# emac register map
Vendor: Texas Instruments
Peripheral module from a debugger description file (folder tm4c129xkczad).
Registers are 32-bit, read-write, no defined reset value unless marked. A register's access mark holds for its fields unless they carry their own. Offsets are as the file gives them; lines under a group give offsets from that group; [hi:lo] are bit positions; {n}, {i} and the like mark numbered series; 'fields as' and 'values as' point back to an identical list; <NAME> marks a mode.

## EMAC0 — EMAC register offsets
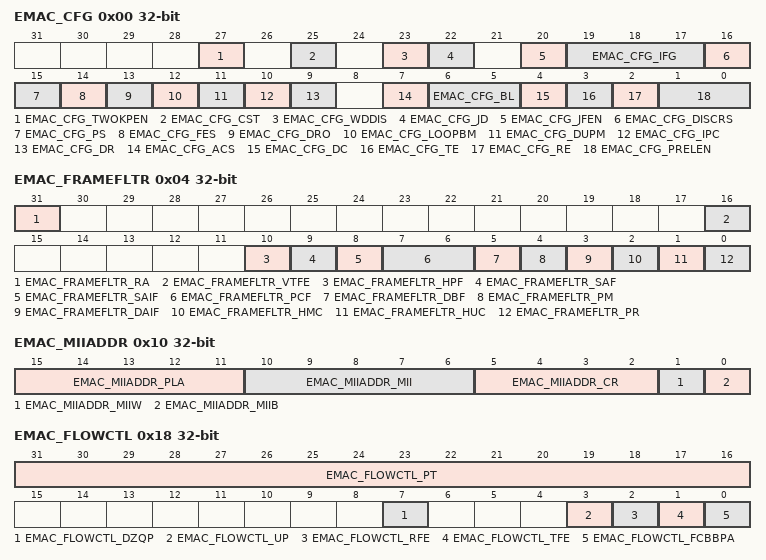
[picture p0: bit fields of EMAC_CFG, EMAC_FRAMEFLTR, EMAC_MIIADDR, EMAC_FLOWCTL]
0x00 EMAC_CFG — Ethernet MAC Configuration
  [27] EMAC_CFG_TWOKPEN — IEEE 802
  [25] EMAC_CFG_CST — CRC Stripping for Type Frames
  [23] EMAC_CFG_WDDIS — Watchdog Disable
  [22] EMAC_CFG_JD — Jabber Disable
  [20] EMAC_CFG_JFEN — Jumbo Frame Enable
  [19:17] EMAC_CFG_IFG — Inter-Frame Gap (IFG)
    0=96 bit times; 1=88 bit times; 2=80 bit times; 3=72 bit times; 4=64 bit times; 5=56 bit times; 6=48 bit times; 7=40 bit times
  [16] EMAC_CFG_DISCRS — Disable Carrier Sense During Transmission
  [15] EMAC_CFG_PS — Port Select
  [14] EMAC_CFG_FES — Speed
  [13] EMAC_CFG_DRO — Disable Receive Own
  [12] EMAC_CFG_LOOPBM — Loopback Mode
  [11] EMAC_CFG_DUPM — Duplex Mode
  [10] EMAC_CFG_IPC — Checksum Offload
  [9] EMAC_CFG_DR — Disable Retry
  [7] EMAC_CFG_ACS — Automatic Pad or CRC Stripping
  [6:5] EMAC_CFG_BL — Back-Off Limit
    0=k = min (n,10); 1=k = min (n,8); 2=k = min (n,4); 3=k = min (n,1)
  [4] EMAC_CFG_DC — Deferral Check
  [3] EMAC_CFG_TE — Transmitter Enable
  [2] EMAC_CFG_RE — Receiver Enable
  [1:0] EMAC_CFG_PRELEN — Preamble Length for Transmit Frames
    0=7 bytes of preamble; 1=5 bytes of preamble; 2=3 bytes of preamble
0x04 EMAC_FRAMEFLTR — Ethernet MAC Frame Filter
  [31] EMAC_FRAMEFLTR_RA — Receive All
  [16] EMAC_FRAMEFLTR_VTFE — VLAN Tag Filter Enable
  [10] EMAC_FRAMEFLTR_HPF — Hash or Perfect Filter
  [9] EMAC_FRAMEFLTR_SAF — Source Address Filter Enable
  [8] EMAC_FRAMEFLTR_SAIF — Source Address (SA) Inverse Filtering
  [7:6] EMAC_FRAMEFLTR_PCF — Pass Control Frames
    0=EMAC_FRAMEFLTR_PCF_ALL (The MAC filters all control frames from reaching application); 1=EMAC_FRAMEFLTR_PCF_PAUSE (MAC forwards all control frames except PAUSE control frames to application even if they fail the address filter); 2=EMAC_FRAMEFLTR_PCF_NONE (MAC forwards all control frames to application even if they fail the address Filter); 3=EMAC_FRAMEFLTR_PCF_ADDR (MAC forwards control frames that pass the address Filter)
  [5] EMAC_FRAMEFLTR_DBF — Disable Broadcast Frames
  [4] EMAC_FRAMEFLTR_PM — Pass All Multicast
  [3] EMAC_FRAMEFLTR_DAIF — Destination Address (DA) Inverse Filtering
  [2] EMAC_FRAMEFLTR_HMC — Hash Multicast
  [1] EMAC_FRAMEFLTR_HUC — Hash Unicast
  [0] EMAC_FRAMEFLTR_PR — Promiscuous Mode
0x08 EMAC_HASHTBLH — Ethernet MAC Hash Table High
  [31:0] EMAC_HASHTBLH_HTH — Hash Table High
0x0C EMAC_HASHTBLL — Ethernet MAC Hash Table Low
  [31:0] EMAC_HASHTBLL_HTL — Hash Table Low
0x10 EMAC_MIIADDR — Ethernet MAC MII Address
  [15:11] EMAC_MIIADDR_PLA — Physical Layer Address
  [10:6] EMAC_MIIADDR_MII — MII Register
  [5:2] EMAC_MIIADDR_CR — Clock Reference Frequency Selection
    0=EMAC_MIIADDR_CR_60_100 (The frequency of the System Clock is 60 to 100 MHz providing a MDIO clock of SYSCLK/42); 4=EMAC_MIIADDR_CR_100_150 (The frequency of the System Clock is 100 to 150 MHz providing a MDIO clock of SYSCLK/62); 8=EMAC_MIIADDR_CR_20_35 (The frequency of the System Clock is 20-35 MHz providing a MDIO clock of System Clock/16); 12=EMAC_MIIADDR_CR_35_60 (The frequency of the System Clock is 35 to 60 MHz providing a MDIO clock of System Clock/26)
  [1] EMAC_MIIADDR_MIIW — MII Write
  [0] EMAC_MIIADDR_MIIB — MII Busy
0x14 EMAC_MIIDATA — Ethernet MAC MII Data Register
  [15:0] EMAC_MIIDATA_DATA — MII Data
0x18 EMAC_FLOWCTL — Ethernet MAC Flow Control
  [31:16] EMAC_FLOWCTL_PT — Pause Time
  [7] EMAC_FLOWCTL_DZQP — Disable Zero-Quanta Pause
  [3] EMAC_FLOWCTL_UP — Unicast Pause Frame Detect
  [2] EMAC_FLOWCTL_RFE — Receive Flow Control Enable
  [1] EMAC_FLOWCTL_TFE — Transmit Flow Control Enable
  [0] EMAC_FLOWCTL_FCBBPA — Flow Control Busy or Back-pressure Activate
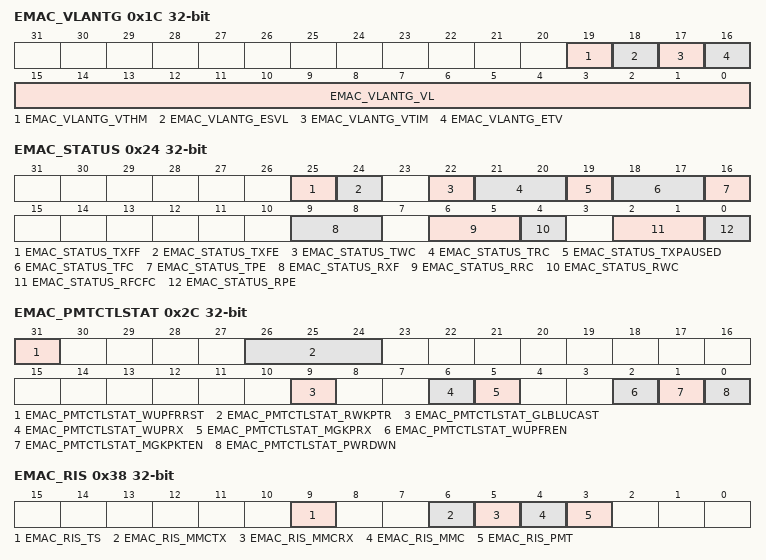
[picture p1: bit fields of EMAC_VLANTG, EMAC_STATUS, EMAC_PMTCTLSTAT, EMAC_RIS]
0x1C EMAC_VLANTG — Ethernet MAC VLAN Tag
  [19] EMAC_VLANTG_VTHM — VLAN Tag Hash Table Match Enable
  [18] EMAC_VLANTG_ESVL — Enable S-VLAN
  [17] EMAC_VLANTG_VTIM — VLAN Tag Inverse Match Enable
  [16] EMAC_VLANTG_ETV — Enable 12-Bit VLAN Tag Comparison
  [15:0] EMAC_VLANTG_VL — VLAN Tag Identifier for Receive Frames
0x24 EMAC_STATUS ro — Ethernet MAC Status
  [25] EMAC_STATUS_TXFF — TX/RX Controller TX FIFO Full Status
  [24] EMAC_STATUS_TXFE — TX/RX Controller TX FIFO Not Empty Status
  [22] EMAC_STATUS_TWC — TX/RX Controller TX FIFO Write Controller Active Status
  [21:20] EMAC_STATUS_TRC — TX/RX Controller's TX FIFO Read Controller Status
    0=EMAC_STATUS_TRC_IDLE (IDLE state); 1=EMAC_STATUS_TRC_READ (READ state (transferring data to MAC transmitter)); 2=EMAC_STATUS_TRC_WAIT (Waiting for TX Status from MAC transmitter); 3=EMAC_STATUS_TRC_WRFLUSH (Writing the received TX Status or flushing the TX FIFO)
  [19] EMAC_STATUS_TXPAUSED — MAC Transmitter PAUSE
  [18:17] EMAC_STATUS_TFC — MAC Transmit Frame Controller Status
    0=EMAC_STATUS_TFC_IDLE (IDLE state); 1=EMAC_STATUS_TFC_STATUS (Waiting for status of previous frame or IFG or backoff period to be over); 2=EMAC_STATUS_TFC_PAUSE (Generating and transmitting a PAUSE control frame (in the full-duplex mode)); 3=EMAC_STATUS_TFC_INPUT (Transferring input frame for transmission)
  [16] EMAC_STATUS_TPE — MAC MII Transmit Protocol Engine Status
  [9:8] EMAC_STATUS_RXF — TX/RX Controller RX FIFO Fill-level Status
    0=EMAC_STATUS_RXF_EMPTY (RX FIFO Empty); 1=EMAC_STATUS_RXF_BELOW (RX FIFO fill level is below the flow-control deactivate threshold); 2=EMAC_STATUS_RXF_ABOVE (RX FIFO fill level is above the flow-control activate threshold); 3=EMAC_STATUS_RXF_FULL (RX FIFO Full)
  [6:5] EMAC_STATUS_RRC — TX/RX Controller Read Controller State
    0=EMAC_STATUS_RRC_IDLE (IDLE state); 1=EMAC_STATUS_RRC_STATUS (Reading frame data); 2=EMAC_STATUS_RRC_DATA (Reading frame status (or timestamp)); 3=EMAC_STATUS_RRC_FLUSH (Flushing the frame data and status)
  [4] EMAC_STATUS_RWC — TX/RX Controller RX FIFO Write Controller Active Status
  [2:1] EMAC_STATUS_RFCFC — MAC Receive Frame Controller FIFO Status
  [0] EMAC_STATUS_RPE — MAC MII Receive Protocol Engine Status
0x28 EMAC_RWUFF — Ethernet MAC Remote Wake-Up Frame Filter
  [31:0] EMAC_RWUFF_WAKEUPFIL — Remote Wake-Up Frame Filter
0x2C EMAC_PMTCTLSTAT — Ethernet MAC PMT Control and Status Register
  [31] EMAC_PMTCTLSTAT_WUPFRRST — Wake-Up Frame Filter Register Pointer Reset
  [26:24] EMAC_PMTCTLSTAT_RWKPTR — Remote Wake-Up FIFO Pointer
  [9] EMAC_PMTCTLSTAT_GLBLUCAST — Global Unicast
  [6] EMAC_PMTCTLSTAT_WUPRX — Wake-Up Frame Received
  [5] EMAC_PMTCTLSTAT_MGKPRX — Magic Packet Received
  [2] EMAC_PMTCTLSTAT_WUPFREN — Wake-Up Frame Enable
  [1] EMAC_PMTCTLSTAT_MGKPKTEN — Magic Packet Enable
  [0] EMAC_PMTCTLSTAT_PWRDWN — Power Down
0x38 EMAC_RIS ro — Ethernet MAC Raw Interrupt Status
  [9] EMAC_RIS_TS — Timestamp Interrupt Status
  [6] EMAC_RIS_MMCTX — MMC Transmit Interrupt Status
  [5] EMAC_RIS_MMCRX — MMC Receive Interrupt Status
  [4] EMAC_RIS_MMC — MMC Interrupt Status
  [3] EMAC_RIS_PMT — PMT Interrupt Status
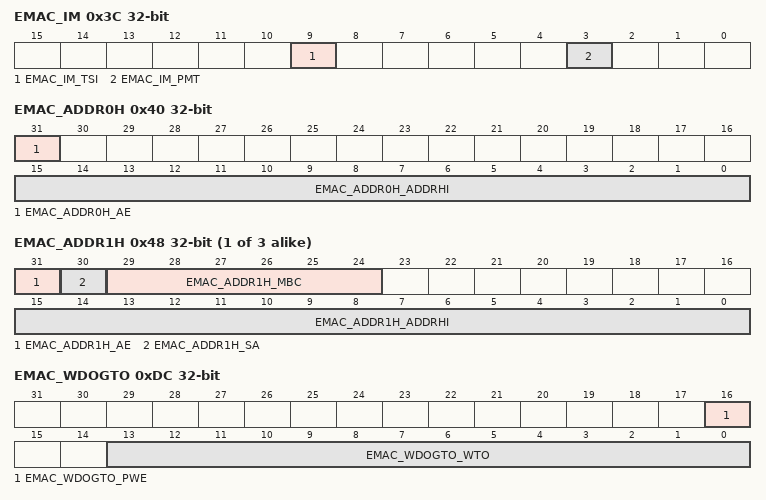
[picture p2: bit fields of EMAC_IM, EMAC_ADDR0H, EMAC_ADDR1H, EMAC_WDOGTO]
0x3C EMAC_IM — Ethernet MAC Interrupt Mask
  [9] EMAC_IM_TSI — Timestamp Interrupt Mask
  [3] EMAC_IM_PMT — PMT Interrupt Mask
0x40 EMAC_ADDR0H — Ethernet MAC Address 0 High
  [31] EMAC_ADDR0H_AE — Address Enable
  [15:0] EMAC_ADDR0H_ADDRHI — MAC Address0 [47:32]
0x44 EMAC_ADDR0L — Ethernet MAC Address 0 Low Register
  [31:0] EMAC_ADDR0L_ADDRLO — MAC Address0 [31:0]
{0x40+8i} EMAC_ADDR{i}H (i=1..3) — Ethernet MAC Address {i} High
  [31] EMAC_ADDR{i}H_AE — Address Enable
  [30] EMAC_ADDR{i}H_SA — Source Address
  [29:24] EMAC_ADDR{i}H_MBC — Mask Byte Control
  [15:0] EMAC_ADDR{i}H_ADDRHI — MAC Address{i} [47:32]
{0x44+8i} EMAC_ADDR{i}L (i=1..3) — Ethernet MAC Address {i} Low
  [31:0] EMAC_ADDR{i}L_ADDRLO — MAC Address{i} [31:0]
0xDC EMAC_WDOGTO — Ethernet MAC Watchdog Timeout
  [16] EMAC_WDOGTO_PWE — Programmable Watchdog Enable
  [13:0] EMAC_WDOGTO_WTO — Watchdog Timeout
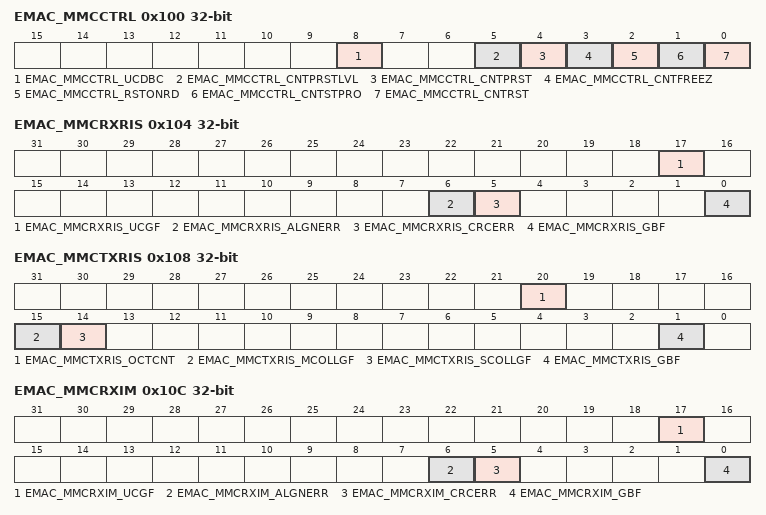
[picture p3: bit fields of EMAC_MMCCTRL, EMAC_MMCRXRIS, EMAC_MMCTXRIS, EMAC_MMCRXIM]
0x100 EMAC_MMCCTRL — Ethernet MAC MMC Control
  [8] EMAC_MMCCTRL_UCDBC — Update MMC Counters for Dropped Broadcast Frames
  [5] EMAC_MMCCTRL_CNTPRSTLVL — Full/Half Preset Level Value
  [4] EMAC_MMCCTRL_CNTPRST — Counters Preset
  [3] EMAC_MMCCTRL_CNTFREEZ — MMC Counter Freeze
  [2] EMAC_MMCCTRL_RSTONRD — Reset on Read
  [1] EMAC_MMCCTRL_CNTSTPRO — Counters Stop Rollover
  [0] EMAC_MMCCTRL_CNTRST — Counters Reset
0x104 EMAC_MMCRXRIS ro — Ethernet MAC MMC Receive Raw Interrupt Status
  [17] EMAC_MMCRXRIS_UCGF — MMC Receive Unicast Good Frame Counter Interrupt Status
  [6] EMAC_MMCRXRIS_ALGNERR — MMC Receive Alignment Error Frame Counter Interrupt Status
  [5] EMAC_MMCRXRIS_CRCERR — MMC Receive CRC Error Frame Counter Interrupt Status
  [0] EMAC_MMCRXRIS_GBF — MMC Receive Good Bad Frame Counter Interrupt Status
0x108 EMAC_MMCTXRIS ro — Ethernet MAC MMC Transmit Raw Interrupt Status
  [20] EMAC_MMCTXRIS_OCTCNT — Octet Counter Interrupt Status
  [15] EMAC_MMCTXRIS_MCOLLGF — MMC Transmit Multiple Collision Good Frame Counter Interrupt Status
  [14] EMAC_MMCTXRIS_SCOLLGF — MMC Transmit Single Collision Good Frame Counter Interrupt Status
  [1] EMAC_MMCTXRIS_GBF — MMC Transmit Good Bad Frame Counter Interrupt Status
0x10C EMAC_MMCRXIM — Ethernet MAC MMC Receive Interrupt Mask
  [17] EMAC_MMCRXIM_UCGF — MMC Receive Unicast Good Frame Counter Interrupt Mask
  [6] EMAC_MMCRXIM_ALGNERR — MMC Receive Alignment Error Frame Counter Interrupt Mask
  [5] EMAC_MMCRXIM_CRCERR — MMC Receive CRC Error Frame Counter Interrupt Mask
  [0] EMAC_MMCRXIM_GBF — MMC Receive Good Bad Frame Counter Interrupt Mask
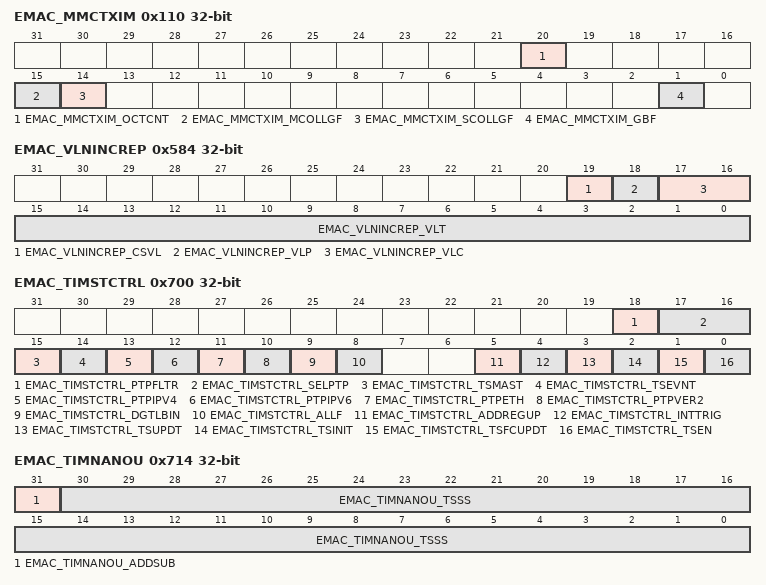
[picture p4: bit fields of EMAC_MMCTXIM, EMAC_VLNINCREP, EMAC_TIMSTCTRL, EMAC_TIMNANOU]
0x110 EMAC_MMCTXIM — Ethernet MAC MMC Transmit Interrupt Mask
  [20] EMAC_MMCTXIM_OCTCNT — MMC Transmit Good Octet Counter Interrupt Mask
  [15] EMAC_MMCTXIM_MCOLLGF — MMC Transmit Multiple Collision Good Frame Counter Interrupt Mask
  [14] EMAC_MMCTXIM_SCOLLGF — MMC Transmit Single Collision Good Frame Counter Interrupt Mask
  [1] EMAC_MMCTXIM_GBF — MMC Transmit Good Bad Frame Counter Interrupt Mask
0x118 EMAC_TXCNTGB ro — Ethernet MAC Transmit Frame Count for Good and Bad Frames
  [31:0] EMAC_TXCNTGB_TXFRMGB — This field indicates the number of good and bad frames transmitted, exclusive of retried frames
0x14C EMAC_TXCNTSCOL ro — Ethernet MAC Transmit Frame Count for Frames Transmitted after Single Collision
  [31:0] EMAC_TXCNTSCOL_TXSNGLCOLG — This field indicates the number of successfully transmitted frames after a single collision in the half-duplex mode
0x150 EMAC_TXCNTMCOL ro — Ethernet MAC Transmit Frame Count for Frames Transmitted after Multiple Collisions
  [31:0] EMAC_TXCNTMCOL_TXMULTCOLG — This field indicates the number of successfully transmitted frames after multiple collisions in the half-duplex mode
0x164 EMAC_TXOCTCNTG ro — Ethernet MAC Transmit Octet Count Good
  [31:0] EMAC_TXOCTCNTG_TXOCTG — This field indicates the number of bytes transmitted, exclusive of preamble, in good frames
0x180 EMAC_RXCNTGB ro — Ethernet MAC Receive Frame Count for Good and Bad Frames
  [31:0] EMAC_RXCNTGB_RXFRMGB — This field indicates the number of received good and bad frames
0x194 EMAC_RXCNTCRCERR ro — Ethernet MAC Receive Frame Count for CRC Error Frames
  [31:0] EMAC_RXCNTCRCERR_RXCRCERR — This field indicates the number of frames received with CRC error
0x198 EMAC_RXCNTALGNERR ro — Ethernet MAC Receive Frame Count for Alignment Error Frames
  [31:0] EMAC_RXCNTALGNERR_RXALGNERR — This field indicates the number of frames received with alignment (dribble) error
0x1C4 EMAC_RXCNTGUNI ro — Ethernet MAC Receive Frame Count for Good Unicast Frames
  [31:0] EMAC_RXCNTGUNI_RXUCASTG — This field indicates the number of received good unicast frames
0x584 EMAC_VLNINCREP — Ethernet MAC VLAN Tag Inclusion or Replacement
  [19] EMAC_VLNINCREP_CSVL — C-VLAN or S-VLAN
  [18] EMAC_VLNINCREP_VLP — VLAN Priority Control
  [17:16] EMAC_VLNINCREP_VLC — VLAN Tag Control in Transmit Frames
    0=EMAC_VLNINCREP_VLC_NONE (No VLAN tag deletion, insertion, or replacement); 1=EMAC_VLNINCREP_VLC_TAGDEL (VLAN tag deletion); 2=EMAC_VLNINCREP_VLC_TAGINS (VLAN tag insertion); 3=EMAC_VLNINCREP_VLC_TAGREP (VLAN tag replacement)
  [15:0] EMAC_VLNINCREP_VLT — VLAN Tag for Transmit Frames
0x588 EMAC_VLANHASH — Ethernet MAC VLAN Hash Table
  [15:0] EMAC_VLANHASH_VLHT — VLAN Hash Table
0x700 EMAC_TIMSTCTRL — Ethernet MAC Timestamp Control
  [18] EMAC_TIMSTCTRL_PTPFLTR — Enable MAC address for PTP Frame Filtering
  [17:16] EMAC_TIMSTCTRL_SELPTP — Select PTP packets for Taking Snapshots
  [15] EMAC_TIMSTCTRL_TSMAST — Enable Snapshot for Messages Relevant to Master
  [14] EMAC_TIMSTCTRL_TSEVNT — Enable Timestamp Snapshot for Event Messages
  [13] EMAC_TIMSTCTRL_PTPIPV4 — Enable Processing of PTP Frames Sent over IPv4-UDP
  [12] EMAC_TIMSTCTRL_PTPIPV6 — Enable Processing of PTP Frames Sent Over IPv6-UDP
  [11] EMAC_TIMSTCTRL_PTPETH — Enable Processing of PTP Over Ethernet Frames
  [10] EMAC_TIMSTCTRL_PTPVER2 — Enable PTP Packet Processing For Version 2 Format
  [9] EMAC_TIMSTCTRL_DGTLBIN — Timestamp Digital or Binary Rollover Control
  [8] EMAC_TIMSTCTRL_ALLF — Enable Timestamp For All Frames
  [5] EMAC_TIMSTCTRL_ADDREGUP — Addend Register Update
  [4] EMAC_TIMSTCTRL_INTTRIG — Timestamp Interrupt Trigger Enable
  [3] EMAC_TIMSTCTRL_TSUPDT — Timestamp Update
  [2] EMAC_TIMSTCTRL_TSINIT — Timestamp Initialize
  [1] EMAC_TIMSTCTRL_TSFCUPDT — Timestamp Fine or Coarse Update
  [0] EMAC_TIMSTCTRL_TSEN — Timestamp Enable
0x704 EMAC_SUBSECINC — Ethernet MAC Sub-Second Increment
  [7:0] EMAC_SUBSECINC_SSINC — Sub-second Increment Value
0x708 EMAC_TIMSEC ro — Ethernet MAC System Time - Seconds
  [31:0] EMAC_TIMSEC_TSS — Timestamp Second
0x70C EMAC_TIMNANO ro — Ethernet MAC System Time - Nanoseconds
  [30:0] EMAC_TIMNANO_TSSS — Timestamp Sub-Seconds
0x710 EMAC_TIMSECU — Ethernet MAC System Time - Seconds Update
  [31:0] EMAC_TIMSECU_TSS — Timestamp Second
0x714 EMAC_TIMNANOU — Ethernet MAC System Time - Nanoseconds Update
  [31] EMAC_TIMNANOU_ADDSUB — Add or subtract time
  [30:0] EMAC_TIMNANOU_TSSS — Timestamp Sub-Second
0x718 EMAC_TIMADD — Ethernet MAC Timestamp Addend
  [31:0] EMAC_TIMADD_TSAR — Timestamp Addend Register
0x71C EMAC_TARGSEC — Ethernet MAC Target Time Seconds
  [31:0] EMAC_TARGSEC_TSTR — Target Time Seconds Register
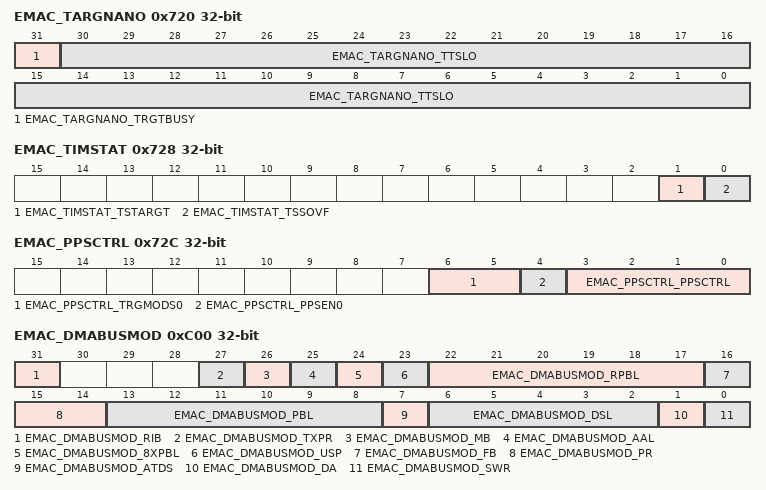
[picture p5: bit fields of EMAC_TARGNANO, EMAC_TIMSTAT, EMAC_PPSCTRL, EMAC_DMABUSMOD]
0x720 EMAC_TARGNANO — Ethernet MAC Target Time Nanoseconds
  [31] EMAC_TARGNANO_TRGTBUSY — Target Time Register Busy
  [30:0] EMAC_TARGNANO_TTSLO — Target Timestamp Low Register
0x724 EMAC_HWORDSEC — Ethernet MAC System Time-Higher Word Seconds
  [15:0] EMAC_HWORDSEC_TSHWR — Target Timestamp Higher Word Register
0x728 EMAC_TIMSTAT ro — Ethernet MAC Timestamp Status
  [1] EMAC_TIMSTAT_TSTARGT — Timestamp Target Time Reached
  [0] EMAC_TIMSTAT_TSSOVF — Timestamp Seconds Overflow
0x72C EMAC_PPSCTRL — Ethernet MAC PPS Control
  [6:5] EMAC_PPSCTRL_TRGMODS0 — Target Time Register Mode for PPS0 Output
    0=EMAC_PPSCTRL_TRGMODS0_INTONLY (Indicates that the Target Time registers are programmed only for generating the interrupt event); 2=EMAC_PPSCTRL_TRGMODS0_INTPPS0 (Indicates that the Target Time registers are programmed for generating the interrupt event and starting or stopping the generation of the EN0PPS output signal); 3=EMAC_PPSCTRL_TRGMODS0_PPS0ONLY (Indicates that the Target Time registers are programmed only for starting or stopping the generation of the EN0PPS output signal. No interrupt is asserted)
  [4] EMAC_PPSCTRL_PPSEN0 — Flexible PPS Output Mode Enable
  [3:0] EMAC_PPSCTRL_PPSCTRL — EN0PPS Output Frequency Control (PPSCTRL) or Command Control (PPSCMD)
0x760 EMAC_PPS0INTVL — Ethernet MAC PPS0 Interval
  [31:0] EMAC_PPS0INTVL_PPS0INT — PPS0 Output Signal Interval
0x764 EMAC_PPS0WIDTH — Ethernet MAC PPS0 Width
  [31:0] EMAC_PPS0WIDTH — EN0PPS Output Signal Width
0xC00 EMAC_DMABUSMOD — Ethernet MAC DMA Bus Mode
  [31] EMAC_DMABUSMOD_RIB — Rebuild Burst
  [27] EMAC_DMABUSMOD_TXPR — Transmit Priority
  [26] EMAC_DMABUSMOD_MB — Mixed Burst
  [25] EMAC_DMABUSMOD_AAL — Address Aligned Beats
  [24] EMAC_DMABUSMOD_8XPBL — 8 x Programmable Burst Length (PBL) Mode
  [23] EMAC_DMABUSMOD_USP — Use Separate Programmable Burst Length (PBL)
  [22:17] EMAC_DMABUSMOD_RPBL — RX DMA Programmable Burst Length (PBL)
  [16] EMAC_DMABUSMOD_FB — Fixed Burst
  [15:14] EMAC_DMABUSMOD_PR — Priority Ratio
  [13:8] EMAC_DMABUSMOD_PBL — Programmable Burst Length
  [7] EMAC_DMABUSMOD_ATDS — Alternate Descriptor Size
  [6:2] EMAC_DMABUSMOD_DSL — Descriptor Skip Length
  [1] EMAC_DMABUSMOD_DA — DMA Arbitration Scheme
  [0] EMAC_DMABUSMOD_SWR — DMA Software Reset
0xC04 EMAC_TXPOLLD wo — Ethernet MAC Transmit Poll Demand
  [31:0] EMAC_TXPOLLD_TPD — Transmit Poll Demand
0xC08 EMAC_RXPOLLD wo — Ethernet MAC Receive Poll Demand
  [31:0] EMAC_RXPOLLD_RPD — Receive Poll Demand
0xC0C EMAC_RXDLADDR — Ethernet MAC Receive Descriptor List Address
  [31:2] EMAC_RXDLADDR_STRXLIST — Start of Receive List
0xC10 EMAC_TXDLADDR — Ethernet MAC Transmit Descriptor List Address
  [31:2] EMAC_TXDLADDR_TXDLADDR — Start of Transmit List Base Address
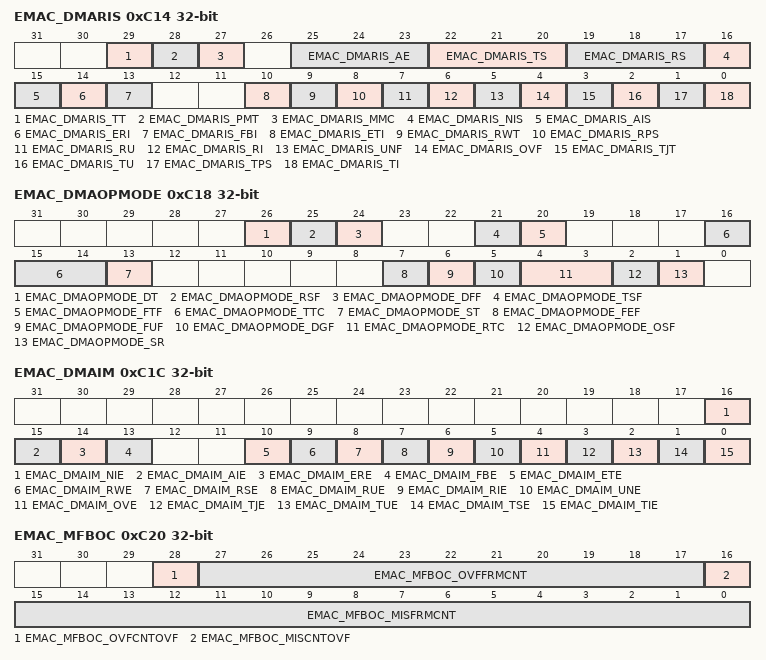
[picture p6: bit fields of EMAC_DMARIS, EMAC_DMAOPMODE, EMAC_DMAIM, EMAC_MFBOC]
0xC14 EMAC_DMARIS — Ethernet MAC DMA Interrupt Status
  [29] EMAC_DMARIS_TT — Timestamp Trigger Interrupt Status
  [28] EMAC_DMARIS_PMT — MAC PMT Interrupt Status
  [27] EMAC_DMARIS_MMC — MAC MMC Interrupt
  [25:23] EMAC_DMARIS_AE — Access Error
    0=EMAC_DMARIS_AE_RXDMAWD (Error during RX DMA Write Data Transfer); 3=EMAC_DMARIS_AE_TXDMARD (Error during TX DMA Read Data Transfer); 4=EMAC_DMARIS_AE_RXDMADW (Error during RX DMA Descriptor Write Access); 5=EMAC_DMARIS_AE_TXDMADW (Error during TX DMA Descriptor Write Access); 6=EMAC_DMARIS_AE_RXDMADR (Error during RX DMA Descriptor Read Access); 7=EMAC_DMARIS_AE_TXDMADR (Error during TX DMA Descriptor Read Access)
  [22:20] EMAC_DMARIS_TS — Transmit Process State
    0=EMAC_DMARIS_TS_STOP (Stopped; Reset or Stop transmit command processed); 1=EMAC_DMARIS_TS_RUNTXTD (Running; Fetching transmit transfer descriptor); 2=EMAC_DMARIS_TS_STATUS (Running; Waiting for status); 3=EMAC_DMARIS_TS_RUNTX (Running; Reading data from host memory buffer and queuing it to transmit buffer (TX FIFO)); 4=EMAC_DMARIS_TS_TSTAMP (Writing Timestamp); 6=EMAC_DMARIS_TS_SUSPEND (Suspended; Transmit descriptor unavailable or transmit buffer underflow); 7=EMAC_DMARIS_TS_RUNCTD (Running; Closing transmit descriptor)
  [19:17] EMAC_DMARIS_RS — Received Process State
    0=EMAC_DMARIS_RS_STOP (Stopped: Reset or stop receive command issued); 1=EMAC_DMARIS_RS_RUNRXTD (Running: Fetching receive transfer descriptor); 3=EMAC_DMARIS_RS_RUNRXD (Running: Waiting for receive packet); 4=EMAC_DMARIS_RS_SUSPEND (Suspended: Receive descriptor unavailable); 5=EMAC_DMARIS_RS_RUNCRD (Running: Closing receive descriptor); 6=EMAC_DMARIS_RS_TSWS (Writing Timestamp); 7=EMAC_DMARIS_RS_RUNTXD (Running: Transferring the receive packet data from receive buffer to host memory)
  [16] EMAC_DMARIS_NIS — Normal Interrupt Summary
  [15] EMAC_DMARIS_AIS — Abnormal Interrupt Summary
  [14] EMAC_DMARIS_ERI — Early Receive Interrupt
  [13] EMAC_DMARIS_FBI — Fatal Bus Error Interrupt
  [10] EMAC_DMARIS_ETI — Early Transmit Interrupt
  [9] EMAC_DMARIS_RWT — Receive Watchdog Timeout
  [8] EMAC_DMARIS_RPS — Receive Process Stopped
  [7] EMAC_DMARIS_RU — Receive Buffer Unavailable
  [6] EMAC_DMARIS_RI — Receive Interrupt
  [5] EMAC_DMARIS_UNF — Transmit Underflow
  [4] EMAC_DMARIS_OVF — Receive Overflow
  [3] EMAC_DMARIS_TJT — Transmit Jabber Timeout
  [2] EMAC_DMARIS_TU — Transmit Buffer Unavailable
  [1] EMAC_DMARIS_TPS — Transmit Process Stopped
  [0] EMAC_DMARIS_TI — Transmit Interrupt
0xC18 EMAC_DMAOPMODE — Ethernet MAC DMA Operation Mode
  [26] EMAC_DMAOPMODE_DT — Disable Dropping of TCP/IP Checksum Error Frames
  [25] EMAC_DMAOPMODE_RSF — Receive Store and Forward
  [24] EMAC_DMAOPMODE_DFF — Disable Flushing of Received Frames
  [21] EMAC_DMAOPMODE_TSF — Transmit Store and Forward
  [20] EMAC_DMAOPMODE_FTF — Flush Transmit FIFO
  [16:14] EMAC_DMAOPMODE_TTC — Transmit Threshold Control
    0=64 bytes; 1=128 bytes; 2=192 bytes; 3=256 bytes; 4=40 bytes; 5=32 bytes; 6=24 bytes; 7=16 bytes
  [13] EMAC_DMAOPMODE_ST — Start or Stop Transmission Command
  [7] EMAC_DMAOPMODE_FEF — Forward Error Frames
  [6] EMAC_DMAOPMODE_FUF — Forward Undersized Good Frames
  [5] EMAC_DMAOPMODE_DGF — Drop Giant Frame Enable
  [4:3] EMAC_DMAOPMODE_RTC — Receive Threshold Control
    0=64 bytes; 1=32 bytes; 2=96 bytes; 3=128 bytes
  [2] EMAC_DMAOPMODE_OSF — Operate on Second Frame
  [1] EMAC_DMAOPMODE_SR — Start or Stop Receive
0xC1C EMAC_DMAIM — Ethernet MAC DMA Interrupt Mask Register
  [16] EMAC_DMAIM_NIE — Normal Interrupt Summary Enable
  [15] EMAC_DMAIM_AIE — Abnormal Interrupt Summary Enable
  [14] EMAC_DMAIM_ERE — Early Receive Interrupt Enable
  [13] EMAC_DMAIM_FBE — Fatal Bus Error Enable
  [10] EMAC_DMAIM_ETE — Early Transmit Interrupt Enable
  [9] EMAC_DMAIM_RWE — Receive Watchdog Timeout Enable
  [8] EMAC_DMAIM_RSE — Receive Stopped Enable
  [7] EMAC_DMAIM_RUE — Receive Buffer Unavailable Enable
  [6] EMAC_DMAIM_RIE — Receive Interrupt Enable
  [5] EMAC_DMAIM_UNE — Underflow Interrupt Enable
  [4] EMAC_DMAIM_OVE — Overflow Interrupt Enable
  [3] EMAC_DMAIM_TJE — Transmit Jabber Timeout Enable
  [2] EMAC_DMAIM_TUE — Transmit Buffer Unvailable Enable
  [1] EMAC_DMAIM_TSE — Transmit Stopped Enable
  [0] EMAC_DMAIM_TIE — Transmit Interrupt Enable
0xC20 EMAC_MFBOC ro — Ethernet MAC Missed Frame and Buffer Overflow Counter
  [28] EMAC_MFBOC_OVFCNTOVF — Overflow Bit for FIFO Overflow Counter
  [27:17] EMAC_MFBOC_OVFFRMCNT — Overflow Frame Counter
  [16] EMAC_MFBOC_MISCNTOVF — Overflow bit for Missed Frame Counter
  [15:0] EMAC_MFBOC_MISFRMCNT — Missed Frame Counter
0xC24 EMAC_RXINTWDT — Ethernet MAC Receive Interrupt Watchdog Timer
  [7:0] EMAC_RXINTWDT_RIWT — Receive Interrupt Watchdog Timer Count
0xC48 EMAC_HOSTXDESC ro — Ethernet MAC Current Host Transmit Descriptor
  [31:0] EMAC_HOSTXDESC_CURTXDESC — Host Transmit Descriptor Address Pointer
0xC4C EMAC_HOSRXDESC ro — Ethernet MAC Current Host Receive Descriptor
  [31:0] EMAC_HOSRXDESC_CURRXDESC — Host Receive Descriptor Address Pointer
0xC50 EMAC_HOSTXBA ro — Ethernet MAC Current Host Transmit Buffer Address
  [31:0] EMAC_HOSTXBA_CURTXBUFA — Host Transmit Buffer Address Pointer
0xC54 EMAC_HOSRXBA ro — Ethernet MAC Current Host Receive Buffer Address
  [31:0] EMAC_HOSRXBA_CURRXBUFA — Host Receive Buffer Address Pointer
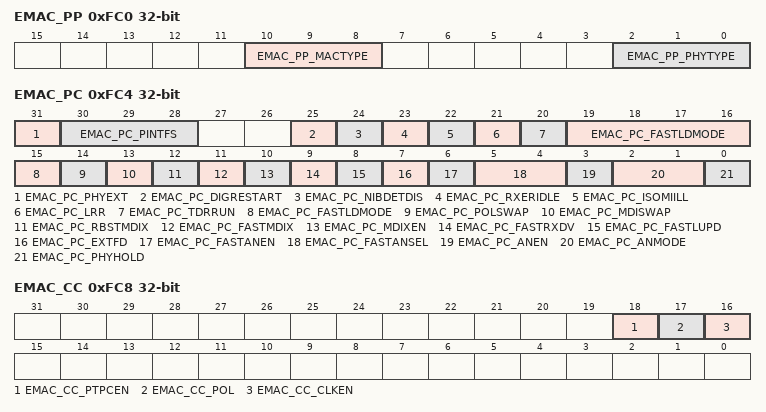
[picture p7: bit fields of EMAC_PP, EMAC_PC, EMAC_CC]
0xFC0 EMAC_PP ro — Ethernet MAC Peripheral Property Register
  [10:8] EMAC_PP_MACTYPE — Ethernet MAC Type
  [2:0] EMAC_PP_PHYTYPE — Ethernet PHY Type
    0=EMAC_PP_PHYTYPE_NONE (No PHY); 3=Snowflake class PHY
0xFC4 EMAC_PC — Ethernet MAC Peripheral Configuration Register
  [31] EMAC_PC_PHYEXT — PHY Select
  [30:28] EMAC_PC_PINTFS — Ethernet Interface Select
    0=EMAC_PC_PINTFS_IMII (MII (default) Used for internal PHY or external PHY connected via MII); 4=EMAC_PC_PINTFS_RMII (RMII: Used for external PHY connected via RMII)
  [25] EMAC_PC_DIGRESTART — PHY Soft Restart
  [24] EMAC_PC_NIBDETDIS — Odd Nibble TXER Detection Disable
  [23] EMAC_PC_RXERIDLE — RXER Detection During Idle
  [22] EMAC_PC_ISOMIILL — Isolate MII in Link Loss
  [21] EMAC_PC_LRR — Link Loss Recovery
  [20] EMAC_PC_TDRRUN — TDR Auto Run
  [19:15] EMAC_PC_FASTLDMODE — Fast Link Down Mode
  [14] EMAC_PC_POLSWAP — Polarity Swap
  [13] EMAC_PC_MDISWAP — MDI Swap
  [12] EMAC_PC_RBSTMDIX — Robust Auto MDI-X
  [11] EMAC_PC_FASTMDIX — Fast Auto MDI-X
  [10] EMAC_PC_MDIXEN — MDIX Enable
  [9] EMAC_PC_FASTRXDV — Fast RXDV Detection
  [8] EMAC_PC_FASTLUPD — FAST Link-Up in Parallel Detect
  [7] EMAC_PC_EXTFD — Extended Full Duplex Ability
  [6] EMAC_PC_FASTANEN — Fast Auto Negotiation Enable
  [5:4] EMAC_PC_FASTANSEL — Fast Auto Negotiation Select
  [3] EMAC_PC_ANEN — Auto Negotiation Enable
  [2:1] EMAC_PC_ANMODE — Auto Negotiation Mode
    0=EMAC_PC_ANMODE_10HD (When ANEN = 0x0, the mode is 10Base-T, Half-Duplex); 1=EMAC_PC_ANMODE_10FD (When ANEN = 0x0, the mode is 10Base-T, Full-Duplex); 2=EMAC_PC_ANMODE_100HD (When ANEN = 0x0, the mode is 100Base-TX, Half-Duplex); 3=EMAC_PC_ANMODE_100FD (When ANEN = 0x0, the mode is 100Base-TX, Full-Duplex)
  [0] EMAC_PC_PHYHOLD — Ethernet PHY Hold
0xFC8 EMAC_CC ro — Ethernet MAC Clock Configuration Register
  [18] EMAC_CC_PTPCEN — PTP Clock Reference Enable
  [17] EMAC_CC_POL — LED Polarity Control
  [16] EMAC_CC_CLKEN — EN0RREF_CLK Signal Enable
0xFD0 EMAC_EPHYRIS ro — Ethernet PHY Raw Interrupt Status
  [0] EMAC_EPHYRIS_INT
0xFD4 EMAC_EPHYIM — Ethernet PHY Interrupt Mask
  [0] EMAC_EPHYIM_INT
0xFD8 EMAC_EPHYMISC — Ethernet PHY Masked Interrupt Status and Clear
  [0] EMAC_EPHYMISC_INT — Ethernet PHY Status and Clear register
